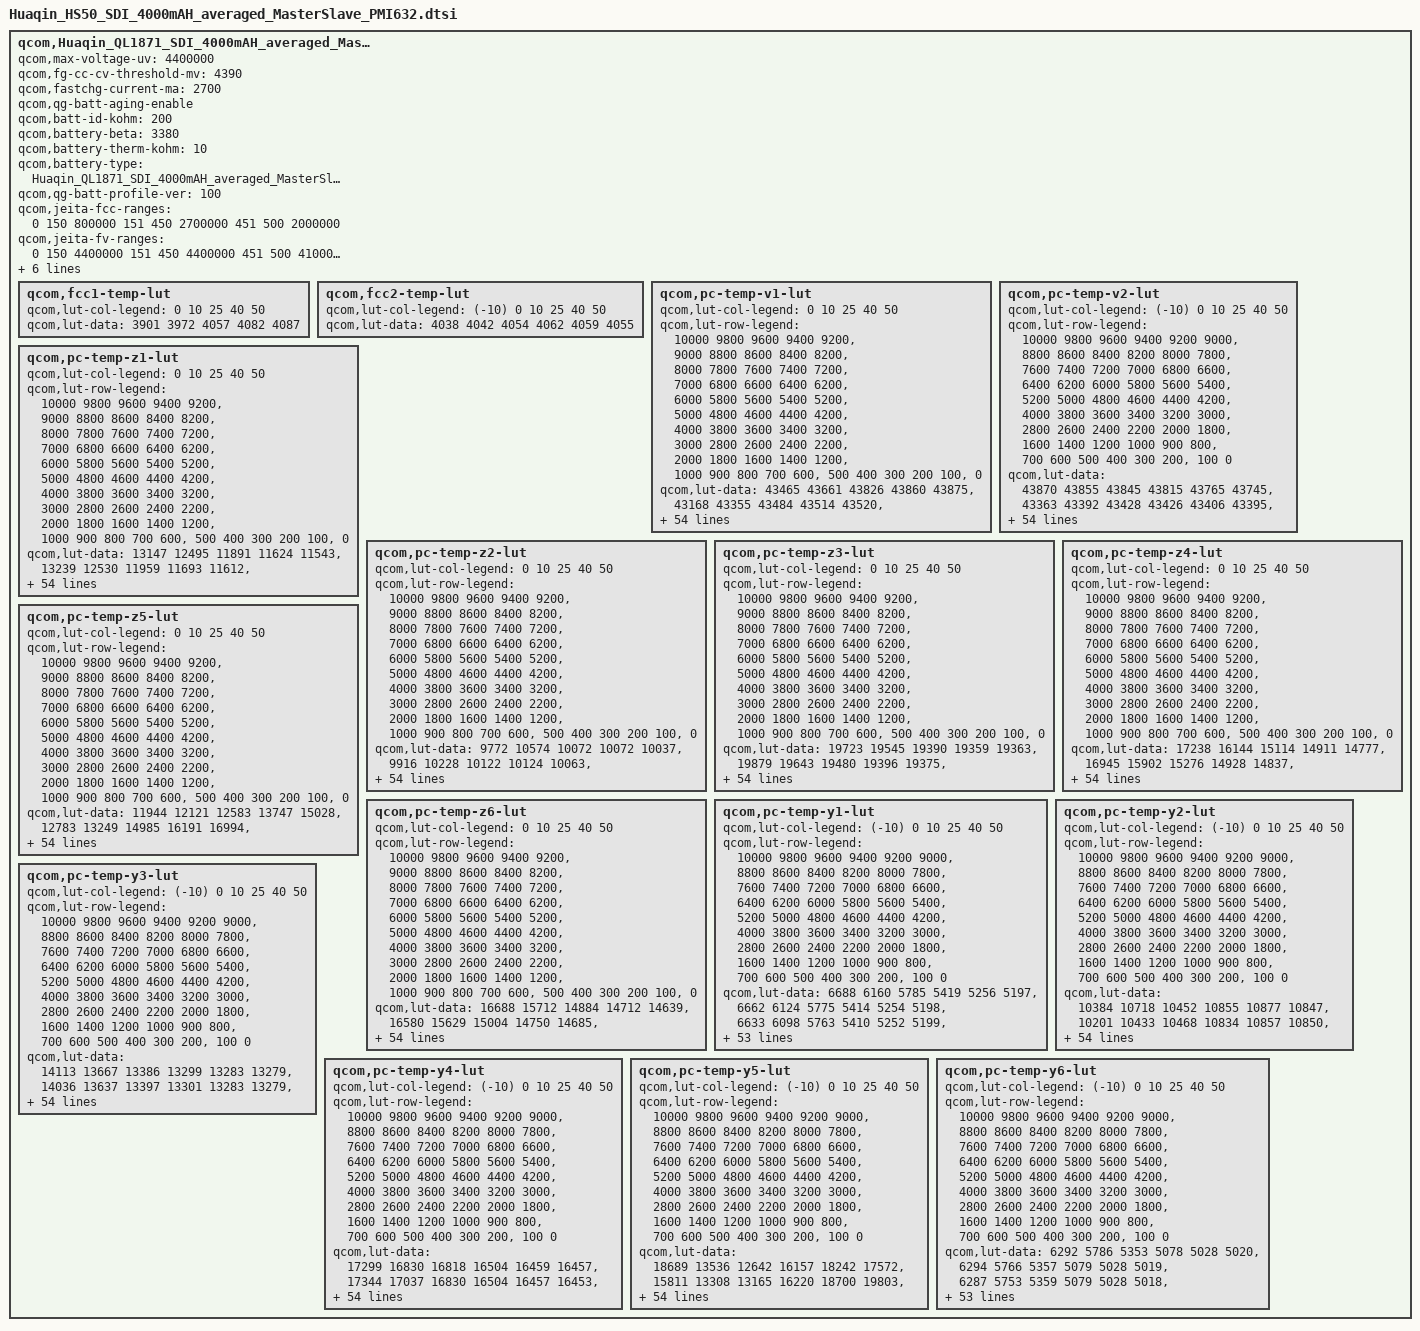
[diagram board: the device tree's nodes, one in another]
qcom,Huaqin_QL1871_SDI_4000mAH_averaged_MasterSlave_PMI632 {
        /* Huaqin_QL1871_SDI_4000mAH_averaged_MasterSlave_PMI632 */
	qcom,max-voltage-uv = <4400000>;
	qcom,fg-cc-cv-threshold-mv = <4390>;
	qcom,fastchg-current-ma = <2700>;
	/* HS60 add for SR-ZQL1695-01-357 Import battery aging by gaochao at 2019/08/29 start */
	qcom,qg-batt-aging-enable;
	/* HS60 add for SR-ZQL1695-01-357 Import battery aging by gaochao at 2019/08/29 end */
	qcom,batt-id-kohm = <200>;
	qcom,battery-beta = <3380>;
	qcom,battery-therm-kohm = <10>;
	qcom,battery-type = "Huaqin_QL1871_SDI_4000mAH_averaged_MasterSlave__PMI632";
	qcom,qg-batt-profile-ver = <100>;

	qcom,jeita-fcc-ranges = <0   150   800000
				 151 450  2700000
				 451 500  2000000>;
	qcom,jeita-fv-ranges =  <0   150  4400000
				 151 450  4400000
				 451 500  4100000>;

	/* HS60 add for SR-ZQL1695-01-357 Import battery aging by gaochao at 2019/08/29 start */
	qcom,vfloat-ranges = <0 299 4400000
	                      300 399 4380000
                              400 699 4360000
                              700 999 4340000
                              1000 9999 4290000>;

	qcom,vbat-rechg-ranges = <0 299 4330000
                                  300 399 4310000
                                  400 699 4290000
                                  700 999 4270000
                                  1000 9999 4220000>;
	/* HS60 add for SR-ZQL1695-01-357 Import battery aging by gaochao at 2019/08/29 end */

	/* COOL = 15 DegC, WARM = 45 DegC */
	qcom,jeita-soft-thresholds = <0x2554 0xFDC>;
	/* COLD = 0 DegC, HOT = 50 DegC */
	/* Huaqin add for HS70-733 modify jeita-hard-thresholds to 50 by qianyingdong at 2019/11/26 start */
	qcom,jeita-hard-thresholds = <0x36B9 0xDBF>;
	/* Huaqin add for HS70-733 modify jeita-hard-thresholds to 50 by qianyingdong at 2019/11/26 end */

	qcom,fcc1-temp-lut {
		qcom,lut-col-legend = <0 10 25 40 50>;
		qcom,lut-data = <3901 3972 4057 4082 4087>;
	};

	qcom,fcc2-temp-lut {
		qcom,lut-col-legend = <(-10) 0 10 25 40 50>;
		qcom,lut-data = <4038 4042 4054 4062 4059 4055>;
	};

	qcom,pc-temp-v1-lut {
		qcom,lut-col-legend = <0 10 25 40 50>;
		qcom,lut-row-legend = <10000 9800 9600 9400 9200>,
			<9000 8800 8600 8400 8200>,
			<8000 7800 7600 7400 7200>,
			<7000 6800 6600 6400 6200>,
			<6000 5800 5600 5400 5200>,
			<5000 4800 4600 4400 4200>,
			<4000 3800 3600 3400 3200>,
			<3000 2800 2600 2400 2200>,
			<2000 1800 1600 1400 1200>,
			<1000 900 800 700 600>,
			<500 400 300 200 100>,
			<0>;
		qcom,lut-data = <43465 43661 43826 43860 43875>,
			<43168 43355 43484 43514 43520>,
			<42910 43074 43198 43228 43235>,
			<42678 42820 42935 42965 42977>,
			<42456 42587 42684 42715 42730>,
			<42244 42362 42447 42478 42496>,
			<42039 42146 42218 42248 42267>,
			<41832 41935 41998 42019 42037>,
			<41621 41723 41782 41795 41810>,
			<41430 41511 41566 41573 41586>,
			<41292 41326 41355 41352 41366>,
			<41162 41190 41176 41150 41153>,
			<40946 41045 41037 40985 40953>,
			<40531 40780 40871 40815 40756>,
			<40153 40376 40555 40566 40541>,
			<39961 40085 40177 40253 40314>,
			<39822 39926 39975 40036 40118>,
			<39706 39804 39865 39914 39962>,
			<39613 39698 39761 39803 39818>,
			<39524 39610 39640 39668 39670>,
			<39416 39504 39510 39520 39523>,
			<39296 39360 39338 39344 39351>,
			<39171 39189 39109 39114 39129>,
			<39043 38984 38904 38900 38916>,
			<38910 38732 38744 38749 38760>,
			<38758 38565 38610 38624 38630>,
			<38584 38492 38511 38516 38517>,
			<38456 38440 38434 38420 38418>,
			<38383 38388 38362 38334 38329>,
			<38330 38341 38290 38256 38246>,
			<38291 38299 38225 38186 38172>,
			<38262 38261 38169 38124 38105>,
			<38239 38226 38120 38069 38047>,
			<38217 38194 38078 38019 37992>,
			<38200 38165 38043 37977 37945>,
			<38180 38137 38011 37936 37900>,
			<38163 38114 37978 37893 37850>,
			<38139 38089 37946 37847 37796>,
			<38097 38046 37900 37790 37732>,
			<38028 37971 37828 37715 37652>,
			<37945 37879 37739 37624 37558>,
			<37831 37772 37638 37521 37452>,
			<37696 37643 37515 37400 37328>,
			<37532 37485 37359 37246 37174>,
			<37379 37325 37205 37099 37030>,
			<37268 37211 37096 37000 36937>,
			<37240 37175 37070 36972 36911>,
			<37211 37152 37048 36954 36892>,
			<37190 37131 37030 36937 36874>,
			<37165 37105 37006 36904 36835>,
			<37030 36973 36840 36710 36618>,
			<36615 36574 36434 36298 36200>,
			<36068 36009 35881 35738 35639>,
			<35323 35237 35119 34974 34874>,
			<34124 34060 33946 33795 33696>,
			<30000 30000 30000 30000 30000>;
	};

	qcom,pc-temp-v2-lut {
		qcom,lut-col-legend = <(-10) 0 10 25 40 50>;
		qcom,lut-row-legend = <10000 9800 9600 9400 9200 9000>,
			<8800 8600 8400 8200 8000 7800>,
			<7600 7400 7200 7000 6800 6600>,
			<6400 6200 6000 5800 5600 5400>,
			<5200 5000 4800 4600 4400 4200>,
			<4000 3800 3600 3400 3200 3000>,
			<2800 2600 2400 2200 2000 1800>,
			<1600 1400 1200 1000 900 800>,
			<700 600 500 400 300 200>,
			<100 0>;
		qcom,lut-data = <43870 43855 43845 43815 43765 43745>,
			<43363 43392 43428 43426 43406 43395>,
			<42944 42992 43064 43084 43084 43079>,
			<42637 42667 42764 42799 42804 42802>,
			<42408 42395 42515 42559 42562 42559>,
			<42187 42166 42280 42329 42328 42324>,
			<41933 41984 42046 42099 42095 42090>,
			<41692 41816 41820 41873 41868 41861>,
			<41520 41591 41594 41648 41643 41636>,
			<41386 41303 41365 41425 41421 41415>,
			<41275 41144 41168 41214 41204 41198>,
			<41198 41113 41025 41028 40992 40986>,
			<41108 41086 40880 40839 40783 40777>,
			<40795 40858 40649 40609 40564 40570>,
			<40045 40176 40320 40342 40339 40361>,
			<39572 39740 40040 40105 40141 40169>,
			<39438 39618 39831 39899 39974 39997>,
			<39338 39522 39651 39724 39819 39833>,
			<39205 39366 39493 39601 39668 39674>,
			<39056 39163 39354 39502 39523 39522>,
			<38877 38981 39196 39365 39358 39356>,
			<38609 38839 39004 39146 39163 39172>,
			<38370 38697 38812 38921 38965 38983>,
			<38278 38495 38650 38742 38775 38791>,
			<38226 38256 38502 38584 38594 38600>,
			<38178 38131 38377 38454 38454 38455>,
			<38130 38083 38274 38346 38347 38346>,
			<38085 38048 38176 38252 38254 38252>,
			<38040 38011 38067 38166 38167 38164>,
			<37997 37975 37961 38089 38088 38084>,
			<37952 37940 37903 38017 38018 38012>,
			<37904 37906 37871 37949 37954 37948>,
			<37855 37870 37844 37888 37895 37888>,
			<37806 37832 37816 37834 37839 37831>,
			<37756 37791 37790 37786 37783 37776>,
			<37705 37747 37756 37740 37717 37701>,
			<37650 37699 37715 37697 37641 37599>,
			<37593 37646 37666 37647 37561 37499>,
			<37529 37585 37600 37580 37483 37414>,
			<37460 37518 37519 37503 37404 37335>,
			<37391 37447 37430 37422 37325 37257>,
			<37322 37367 37329 37334 37244 37180>,
			<37253 37279 37230 37220 37139 37076>,
			<37186 37180 37130 37084 37008 36943>,
			<37115 37069 37028 36955 36872 36810>,
			<37035 36962 36937 36886 36818 36761>,
			<36991 36915 36893 36870 36805 36752>,
			<36942 36870 36848 36855 36792 36738>,
			<36881 36826 36799 36830 36768 36713>,
			<36791 36755 36715 36776 36707 36642>,
			<36612 36614 36548 36579 36472 36380>,
			<36271 36285 36202 36123 35994 35891>,
			<35732 35731 35632 35499 35362 35253>,
			<34929 34932 34821 34644 34495 34379>,
			<33597 33640 33535 33359 33206 33068>,
			<29083 28754 28799 29150 29064 29071>;
	};

	qcom,pc-temp-z1-lut {
		qcom,lut-col-legend = <0 10 25 40 50>;
		qcom,lut-row-legend = <10000 9800 9600 9400 9200>,
			<9000 8800 8600 8400 8200>,
			<8000 7800 7600 7400 7200>,
			<7000 6800 6600 6400 6200>,
			<6000 5800 5600 5400 5200>,
			<5000 4800 4600 4400 4200>,
			<4000 3800 3600 3400 3200>,
			<3000 2800 2600 2400 2200>,
			<2000 1800 1600 1400 1200>,
			<1000 900 800 700 600>,
			<500 400 300 200 100>,
			<0>;
		qcom,lut-data = <13147 12495 11891 11624 11543>,
			<13239 12530 11959 11693 11612>,
			<13247 12548 11956 11696 11616>,
			<13224 12543 11950 11698 11617>,
			<13212 12537 11946 11696 11617>,
			<13202 12535 11940 11692 11617>,
			<13189 12531 11934 11690 11617>,
			<13185 12525 11928 11688 11616>,
			<13179 12525 11924 11688 11616>,
			<13177 12526 11923 11687 11615>,
			<13169 12523 11924 11687 11614>,
			<13152 12513 11922 11686 11613>,
			<13135 12497 11917 11685 11614>,
			<13099 12475 11911 11683 11615>,
			<13063 12446 11899 11678 11614>,
			<13036 12433 11887 11669 11610>,
			<13014 12435 11885 11666 11608>,
			<13009 12439 11892 11669 11610>,
			<13030 12446 11898 11673 11612>,
			<13055 12463 11902 11675 11613>,
			<13067 12473 11906 11678 11614>,
			<13071 12472 11909 11679 11614>,
			<13070 12469 11911 11679 11615>,
			<13070 12472 11914 11680 11615>,
			<13071 12477 11917 11682 11617>,
			<13074 12481 11922 11686 11620>,
			<13079 12478 11926 11689 11623>,
			<13087 12473 11931 11692 11626>,
			<13101 12478 11935 11696 11629>,
			<13117 12494 11936 11699 11631>,
			<13122 12507 11938 11703 11633>,
			<13116 12514 11941 11707 11636>,
			<13111 12520 11946 11710 11641>,
			<13115 12519 11952 11714 11644>,
			<13124 12511 11957 11716 11647>,
			<13131 12507 11962 11719 11649>,
			<13141 12511 11969 11723 11651>,
			<13152 12519 11978 11727 11653>,
			<13162 12531 11981 11730 11656>,
			<13172 12553 11980 11733 11659>,
			<13187 12568 11979 11735 11661>,
			<13226 12573 11986 11739 11664>,
			<13244 12576 11996 11742 11667>,
			<13232 12570 11998 11745 11669>,
			<13237 12580 12002 11749 11671>,
			<13216 12613 12010 11750 11672>,
			<13261 12583 12011 11750 11672>,
			<13251 12609 12018 11752 11672>,
			<13249 12595 12014 11753 11673>,
			<13258 12587 12026 11758 11677>,
			<13266 12601 12028 11765 11683>,
			<13264 12645 12030 11774 11690>,
			<13307 12625 12050 11783 11702>,
			<13306 12702 12072 11802 11717>,
			<13306 12702 12072 11802 11717>,
			<13306 12702 12072 11802 11717>;
	};

	qcom,pc-temp-z2-lut {
		qcom,lut-col-legend = <0 10 25 40 50>;
		qcom,lut-row-legend = <10000 9800 9600 9400 9200>,
			<9000 8800 8600 8400 8200>,
			<8000 7800 7600 7400 7200>,
			<7000 6800 6600 6400 6200>,
			<6000 5800 5600 5400 5200>,
			<5000 4800 4600 4400 4200>,
			<4000 3800 3600 3400 3200>,
			<3000 2800 2600 2400 2200>,
			<2000 1800 1600 1400 1200>,
			<1000 900 800 700 600>,
			<500 400 300 200 100>,
			<0>;
		qcom,lut-data = <9772 10574 10072 10072 10037>,
			<9916 10228 10122 10124 10063>,
			<9965 10026 10152 10175 10066>,
			<9989 10012 10166 10237 10061>,
			<10005 10010 10156 10244 10053>,
			<10019 10006 10133 10205 10035>,
			<10030 9994 10149 10170 10023>,
			<10030 9983 10331 10156 10023>,
			<10026 9982 10484 10144 10026>,
			<10019 9984 10618 10126 10028>,
			<10006 9987 10871 10105 10034>,
			<9987 9991 10944 10099 10042>,
			<9966 9998 10907 10078 10049>,
			<9939 10014 10839 10052 10058>,
			<9920 10043 10595 10083 10077>,
			<9915 10056 10249 10168 10114>,
			<9913 10054 10163 10197 10130>,
			<9914 10051 10153 10143 10120>,
			<9921 10062 10152 10091 10110>,
			<9934 10109 10175 10099 10118>,
			<9951 10155 10217 10130 10147>,
			<9977 10195 10269 10173 10179>,
			<10004 10229 10354 10263 10216>,
			<10033 10247 10397 10322 10248>,
			<10061 10259 10329 10297 10270>,
			<10086 10264 10241 10248 10290>,
			<10110 10256 10242 10228 10284>,
			<10128 10245 10289 10265 10205>,
			<10140 10244 10319 10299 10127>,
			<10149 10245 10327 10253 10086>,
			<10156 10248 10331 10176 10056>,
			<10161 10252 10330 10147 10053>,
			<10167 10259 10323 10126 10061>,
			<10175 10269 10321 10118 10074>,
			<10184 10286 10333 10136 10096>,
			<10194 10298 10349 10169 10128>,
			<10206 10305 10364 10210 10172>,
			<10219 10310 10380 10267 10236>,
			<10234 10320 10394 10297 10274>,
			<10251 10338 10417 10309 10290>,
			<10264 10348 10433 10316 10298>,
			<10273 10348 10427 10317 10295>,
			<10285 10347 10418 10317 10287>,
			<10310 10355 10420 10309 10284>,
			<10497 10435 10441 10313 10283>,
			<10557 10507 10470 10326 10262>,
			<10557 10505 10453 10326 10264>,
			<10556 10502 10437 10337 10268>,
			<10561 10511 10429 10336 10265>,
			<10607 10516 10427 10383 10363>,
			<10620 10544 10453 10356 10268>,
			<10567 10489 10380 10227 10113>,
			<10365 10433 10339 10154 10059>,
			<9693 10367 10264 10112 10019>,
			<9693 10367 10264 10112 10019>,
			<9693 10367 10264 10112 10019>;
	};

	qcom,pc-temp-z3-lut {
		qcom,lut-col-legend = <0 10 25 40 50>;
		qcom,lut-row-legend = <10000 9800 9600 9400 9200>,
			<9000 8800 8600 8400 8200>,
			<8000 7800 7600 7400 7200>,
			<7000 6800 6600 6400 6200>,
			<6000 5800 5600 5400 5200>,
			<5000 4800 4600 4400 4200>,
			<4000 3800 3600 3400 3200>,
			<3000 2800 2600 2400 2200>,
			<2000 1800 1600 1400 1200>,
			<1000 900 800 700 600>,
			<500 400 300 200 100>,
			<0>;
		qcom,lut-data = <19723 19545 19390 19359 19363>,
			<19879 19643 19480 19396 19375>,
			<19893 19700 19493 19411 19386>,
			<19880 19702 19498 19420 19391>,
			<19865 19697 19498 19421 19392>,
			<19841 19691 19496 19421 19393>,
			<19813 19680 19497 19420 19393>,
			<19795 19667 19505 19416 19392>,
			<19784 19658 19510 19411 19388>,
			<19771 19651 19512 19407 19385>,
			<19745 19641 19515 19404 19379>,
			<19717 19613 19513 19400 19376>,
			<19716 19588 19505 19388 19374>,
			<19755 19589 19493 19377 19373>,
			<19786 19598 19481 19380 19373>,
			<19775 19601 19467 19393 19375>,
			<19743 19588 19451 19396 19375>,
			<19712 19567 19430 19380 19367>,
			<19674 19548 19417 19364 19357>,
			<19647 19528 19412 19362 19352>,
			<19645 19520 19409 19361 19348>,
			<19646 19527 19414 19362 19348>,
			<19648 19537 19433 19371 19353>,
			<19653 19546 19444 19378 19357>,
			<19660 19554 19431 19368 19356>,
			<19668 19558 19413 19352 19353>,
			<19678 19554 19411 19352 19354>,
			<19683 19548 19413 19377 19373>,
			<19680 19545 19416 19395 19387>,
			<19672 19542 19430 19397 19386>,
			<19665 19541 19443 19396 19384>,
			<19656 19540 19445 19394 19381>,
			<19648 19540 19445 19389 19375>,
			<19641 19540 19445 19384 19369>,
			<19635 19539 19442 19379 19363>,
			<19630 19539 19437 19374 19356>,
			<19624 19536 19432 19371 19352>,
			<19618 19531 19428 19368 19348>,
			<19614 19527 19424 19366 19347>,
			<19610 19524 19422 19365 19348>,
			<19604 19521 19419 19364 19349>,
			<19595 19516 19414 19363 19350>,
			<19585 19511 19410 19362 19354>,
			<19577 19504 19408 19363 19357>,
			<19527 19482 19401 19361 19357>,
			<19506 19459 19393 19353 19347>,
			<19494 19459 19387 19347 19338>,
			<19494 19456 19386 19343 19333>,
			<19488 19451 19385 19341 19330>,
			<19466 19446 19367 19336 19323>,
			<19472 19445 19375 19345 19342>,
			<19488 19449 19386 19359 19352>,
			<19426 19452 19371 19360 19354>,
			<19278 19446 19375 19362 19355>,
			<19278 19446 19375 19362 19355>,
			<19278 19446 19375 19362 19355>;
	};

	qcom,pc-temp-z4-lut {
		qcom,lut-col-legend = <0 10 25 40 50>;
		qcom,lut-row-legend = <10000 9800 9600 9400 9200>,
			<9000 8800 8600 8400 8200>,
			<8000 7800 7600 7400 7200>,
			<7000 6800 6600 6400 6200>,
			<6000 5800 5600 5400 5200>,
			<5000 4800 4600 4400 4200>,
			<4000 3800 3600 3400 3200>,
			<3000 2800 2600 2400 2200>,
			<2000 1800 1600 1400 1200>,
			<1000 900 800 700 600>,
			<500 400 300 200 100>,
			<0>;
		qcom,lut-data = <17238 16144 15114 14911 14777>,
			<16945 15902 15276 14928 14837>,
			<16599 15682 15153 14909 14843>,
			<16206 15479 15005 14854 14818>,
			<15898 15292 14934 14817 14795>,
			<15688 15156 14881 14790 14774>,
			<15523 15060 14831 14767 14756>,
			<15398 14987 14778 14747 14740>,
			<15300 14934 14738 14732 14726>,
			<15216 14893 14711 14725 14719>,
			<15137 14856 14685 14721 14715>,
			<15069 14813 14664 14717 14711>,
			<15013 14784 14644 14709 14702>,
			<14968 14786 14634 14703 14694>,
			<14928 14799 14670 14708 14694>,
			<14886 14804 14732 14723 14698>,
			<14847 14786 14740 14727 14699>,
			<14827 14760 14714 14701 14685>,
			<14820 14743 14694 14673 14668>,
			<14813 14728 14688 14665 14661>,
			<14799 14723 14685 14661 14657>,
			<14779 14728 14692 14665 14660>,
			<14771 14738 14731 14714 14711>,
			<14771 14773 14771 14766 14761>,
			<14771 14861 14810 14791 14771>,
			<14785 14906 14841 14809 14775>,
			<14836 14894 14839 14805 14772>,
			<14865 14873 14820 14765 14738>,
			<14864 14856 14798 14729 14706>,
			<14862 14841 14773 14714 14694>,
			<14858 14826 14751 14704 14686>,
			<14846 14812 14739 14697 14681>,
			<14832 14800 14731 14692 14676>,
			<14820 14790 14727 14689 14674>,
			<14808 14782 14725 14688 14674>,
			<14796 14775 14724 14687 14674>,
			<14783 14770 14724 14688 14675>,
			<14774 14766 14726 14693 14681>,
			<14768 14767 14729 14698 14687>,
			<14763 14770 14735 14706 14694>,
			<14762 14772 14739 14712 14700>,
			<14763 14766 14734 14708 14695>,
			<14763 14756 14723 14699 14686>,
			<14754 14747 14717 14698 14687>,
			<14726 14725 14701 14692 14683>,
			<14716 14707 14684 14675 14667>,
			<14717 14700 14680 14673 14668>,
			<14707 14693 14668 14664 14659>,
			<14705 14686 14657 14647 14642>,
			<14718 14683 14664 14642 14636>,
			<14712 14690 14672 14657 14648>,
			<14723 14703 14675 14655 14650>,
			<14803 14705 14693 14656 14650>,
			<14974 14710 14690 14655 14649>,
			<14974 14710 14690 14655 14649>,
			<14974 14710 14690 14655 14649>;
	};

	qcom,pc-temp-z5-lut {
		qcom,lut-col-legend = <0 10 25 40 50>;
		qcom,lut-row-legend = <10000 9800 9600 9400 9200>,
			<9000 8800 8600 8400 8200>,
			<8000 7800 7600 7400 7200>,
			<7000 6800 6600 6400 6200>,
			<6000 5800 5600 5400 5200>,
			<5000 4800 4600 4400 4200>,
			<4000 3800 3600 3400 3200>,
			<3000 2800 2600 2400 2200>,
			<2000 1800 1600 1400 1200>,
			<1000 900 800 700 600>,
			<500 400 300 200 100>,
			<0>;
		qcom,lut-data = <11944 12121 12583 13747 15028>,
			<12783 13249 14985 16191 16994>,
			<13216 14218 15867 17368 18248>,
			<13482 14993 16527 18555 19010>,
			<13727 15645 17163 19298 19578>,
			<13972 16303 17754 19763 19972>,
			<14218 16949 18755 20211 20393>,
			<14545 17645 20978 20796 21185>,
			<14994 18680 23411 21321 21981>,
			<15259 19994 25851 21600 22041>,
			<15269 20478 29201 21790 21710>,
			<15259 20284 32965 21715 21529>,
			<15663 20068 38027 20509 22080>,
			<18435 20975 40905 19142 23206>,
			<20692 23891 35767 20276 24784>,
			<20718 25216 26543 23824 27133>,
			<20596 24376 23290 25029 28082>,
			<20348 23353 22076 23286 27294>,
			<19310 23193 21639 21683 26395>,
			<18357 23299 22468 22501 26896>,
			<18921 23666 24278 25032 28533>,
			<21243 29042 28460 27786 29356>,
			<24130 36269 39872 31444 29446>,
			<27943 39106 45940 33607 29176>,
			<32587 40750 36496 28043 25457>,
			<37967 41284 23622 18233 18490>,
			<44667 37279 20552 16442 16941>,
			<47829 31543 19459 18338 19139>,
			<45536 29383 19196 20230 21690>,
			<41383 28239 21108 21676 23540>,
			<38334 27830 24134 23180 25197>,
			<35771 28247 26638 24369 26501>,
			<33917 29130 29118 25803 27637>,
			<32772 30367 31073 27046 28262>,
			<31953 32413 32803 28241 28512>,
			<31795 33813 33849 29163 28659>,
			<32036 34354 33701 29214 28443>,
			<32435 34694 33019 28750 27422>,
			<33246 34666 32058 28062 26220>,
			<34503 34172 30235 26408 24509>,
			<34804 33466 28262 24579 23163>,
			<32303 32312 26521 23397 23338>,
			<30849 30950 25280 22638 24004>,
			<31613 29574 25269 22759 24905>,
			<31721 30086 25627 22775 25327>,
			<30564 28865 26333 21950 23000>,
			<26609 29328 24309 20405 19449>,
			<27407 28405 25409 20245 19361>,
			<26290 27931 27129 22713 22227>,
			<21323 27201 21263 22780 22393>,
			<23045 25725 21284 20826 23237>,
			<23669 22618 20563 21107 22294>,
			<17188 21394 16792 20223 21227>,
			<11348 19636 16847 19686 20016>,
			<11348 19636 16847 19686 20016>,
			<11348 19636 16847 19686 20016>;
	};

	qcom,pc-temp-z6-lut {
		qcom,lut-col-legend = <0 10 25 40 50>;
		qcom,lut-row-legend = <10000 9800 9600 9400 9200>,
			<9000 8800 8600 8400 8200>,
			<8000 7800 7600 7400 7200>,
			<7000 6800 6600 6400 6200>,
			<6000 5800 5600 5400 5200>,
			<5000 4800 4600 4400 4200>,
			<4000 3800 3600 3400 3200>,
			<3000 2800 2600 2400 2200>,
			<2000 1800 1600 1400 1200>,
			<1000 900 800 700 600>,
			<500 400 300 200 100>,
			<0>;
		qcom,lut-data = <16688 15712 14884 14712 14639>,
			<16580 15629 15004 14750 14685>,
			<16416 15541 14955 14746 14692>,
			<16193 15444 14894 14730 14685>,
			<16006 15342 14860 14716 14679>,
			<15871 15261 14833 14704 14670>,
			<15760 15201 14811 14693 14662>,
			<15675 15153 14791 14682 14654>,
			<15607 15116 14775 14672 14647>,
			<15546 15086 14764 14667 14641>,
			<15482 15055 14756 14663 14636>,
			<15423 15013 14744 14659 14632>,
			<15382 14982 14727 14648 14627>,
			<15353 14978 14717 14639 14623>,
			<15326 14978 14724 14643 14623>,
			<15291 14976 14735 14654 14624>,
			<15255 14961 14734 14657 14624>,
			<15230 14938 14711 14637 14614>,
			<15212 14922 14694 14616 14601>,
			<15200 14908 14690 14612 14595>,
			<15195 14903 14688 14609 14591>,
			<15193 14908 14693 14612 14592>,
			<15192 14920 14722 14640 14616>,
			<15195 14942 14745 14664 14640>,
			<15202 14985 14754 14668 14644>,
			<15217 15006 14760 14670 14646>,
			<15247 15000 14759 14669 14646>,
			<15263 14991 14753 14665 14642>,
			<15262 14984 14747 14661 14637>,
			<15260 14977 14744 14657 14633>,
			<15256 14971 14742 14652 14628>,
			<15248 14966 14740 14648 14624>,
			<15240 14962 14738 14644 14619>,
			<15234 14960 14736 14640 14615>,
			<15228 14958 14733 14636 14611>,
			<15224 14957 14731 14634 14608>,
			<15219 14954 14730 14634 14607>,
			<15216 14953 14729 14634 14608>,
			<15216 14953 14729 14635 14608>,
			<15218 14956 14731 14637 14611>,
			<15219 14958 14732 14640 14614>,
			<15219 14956 14729 14638 14614>,
			<15220 14952 14723 14635 14612>,
			<15220 14949 14721 14635 14614>,
			<15202 14939 14713 14632 14613>,
			<15191 14926 14704 14621 14601>,
			<15186 14924 14699 14617 14597>,
			<15182 14920 14694 14611 14590>,
			<15178 14915 14689 14603 14581>,
			<15176 14915 14684 14598 14575>,
			<15185 14922 14694 14611 14591>,
			<15206 14937 14704 14620 14601>,
			<15221 14948 14708 14624 14604>,
			<15245 14964 14716 14628 14608>,
			<15245 14964 14716 14628 14608>,
			<15245 14964 14716 14628 14608>;
	};

	qcom,pc-temp-y1-lut {
		qcom,lut-col-legend = <(-10) 0 10 25 40 50>;
		qcom,lut-row-legend = <10000 9800 9600 9400 9200 9000>,
			<8800 8600 8400 8200 8000 7800>,
			<7600 7400 7200 7000 6800 6600>,
			<6400 6200 6000 5800 5600 5400>,
			<5200 5000 4800 4600 4400 4200>,
			<4000 3800 3600 3400 3200 3000>,
			<2800 2600 2400 2200 2000 1800>,
			<1600 1400 1200 1000 900 800>,
			<700 600 500 400 300 200>,
			<100 0>;
		qcom,lut-data = <6688 6160 5785 5419 5256 5197>,
			<6662 6124 5775 5414 5254 5198>,
			<6633 6098 5763 5410 5252 5199>,
			<6606 6081 5752 5406 5250 5198>,
			<6587 6070 5743 5402 5249 5198>,
			<6580 6067 5740 5400 5247 5197>,
			<6600 6075 5741 5397 5246 5197>,
			<6628 6087 5743 5395 5244 5195>,
			<6629 6090 5741 5394 5243 5195>,
			<6610 6094 5736 5394 5241 5194>,
			<6600 6096 5731 5394 5240 5194>,
			<6617 6092 5726 5392 5238 5193>,
			<6638 6089 5723 5390 5237 5192>,
			<6635 6091 5727 5390 5235 5191>,
			<6617 6095 5739 5391 5234 5189>,
			<6610 6100 5745 5391 5234 5189>,
			<6626 6106 5748 5391 5235 5190>,
			<6647 6111 5750 5391 5237 5192>,
			<6651 6120 5750 5391 5236 5192>,
			<6653 6138 5749 5391 5234 5191>,
			<6655 6145 5750 5390 5233 5191>,
			<6663 6131 5754 5391 5234 5191>,
			<6669 6116 5757 5392 5235 5191>,
			<6667 6114 5756 5394 5237 5192>,
			<6664 6113 5754 5397 5238 5193>,
			<6657 6113 5756 5400 5240 5195>,
			<6622 6114 5764 5402 5242 5197>,
			<6590 6116 5773 5405 5244 5198>,
			<6597 6122 5782 5409 5246 5200>,
			<6621 6131 5791 5415 5248 5201>,
			<6636 6133 5792 5421 5251 5203>,
			<6652 6132 5784 5428 5255 5206>,
			<6663 6132 5779 5433 5258 5209>,
			<6654 6137 5784 5437 5262 5212>,
			<6629 6147 5793 5440 5265 5214>,
			<6618 6148 5796 5441 5269 5216>,
			<6610 6137 5795 5442 5272 5218>,
			<6601 6129 5794 5444 5274 5221>,
			<6596 6125 5792 5447 5277 5223>,
			<6596 6115 5788 5451 5279 5225>,
			<6602 6117 5786 5458 5282 5227>,
			<6613 6129 5786 5466 5284 5228>,
			<6616 6126 5794 5473 5287 5231>,
			<6606 6115 5806 5477 5291 5234>,
			<6615 6121 5810 5485 5298 5238>,
			<6611 6168 5802 5488 5302 5242>,
			<6624 6140 5804 5498 5304 5243>,
			<6626 6155 5806 5492 5304 5242>,
			<6632 6143 5814 5498 5303 5240>,
			<6655 6140 5819 5500 5303 5240>,
			<6667 6149 5818 5495 5303 5242>,
			<6629 6154 5838 5501 5314 5249>,
			<6648 6193 5850 5523 5326 5258>,
			<6714 6204 5851 5546 5336 5269>,
			<6714 6204 5851 5546 5336 5269>,
			<6714 6204 5851 5546 5336 5269>;
	};

	qcom,pc-temp-y2-lut {
		qcom,lut-col-legend = <(-10) 0 10 25 40 50>;
		qcom,lut-row-legend = <10000 9800 9600 9400 9200 9000>,
			<8800 8600 8400 8200 8000 7800>,
			<7600 7400 7200 7000 6800 6600>,
			<6400 6200 6000 5800 5600 5400>,
			<5200 5000 4800 4600 4400 4200>,
			<4000 3800 3600 3400 3200 3000>,
			<2800 2600 2400 2200 2000 1800>,
			<1600 1400 1200 1000 900 800>,
			<700 600 500 400 300 200>,
			<100 0>;
		qcom,lut-data = <10384 10718 10452 10855 10877 10847>,
			<10201 10433 10468 10834 10857 10850>,
			<10122 10243 10478 10812 10831 10845>,
			<10123 10130 10483 10792 10802 10835>,
			<10176 10075 10485 10773 10773 10820>,
			<10257 10063 10486 10756 10748 10802>,
			<10457 10157 10489 10742 10718 10767>,
			<10673 10286 10490 10728 10693 10732>,
			<10654 10298 10462 10716 10689 10725>,
			<10447 10264 10385 10704 10691 10726>,
			<10336 10247 10355 10691 10692 10724>,
			<10461 10286 10630 10668 10677 10702>,
			<10620 10368 10950 10647 10661 10677>,
			<10494 10482 10921 10670 10662 10682>,
			<9963 10673 10742 10753 10675 10705>,
			<9697 10940 10670 10815 10695 10718>,
			<9689 11539 10726 10851 10758 10714>,
			<9684 12091 10811 10889 10838 10711>,
			<9681 11848 10888 10955 10899 10736>,
			<9679 10882 10971 11043 10955 10805>,
			<9677 10330 11031 11077 11012 10874>,
			<9674 10198 11070 11084 11085 10953>,
			<9672 10103 11104 11087 11130 11008>,
			<9670 9959 11157 11086 11086 10996>,
			<9669 9785 11220 11086 10993 10955>,
			<9668 9716 11220 11093 10970 10948>,
			<9667 9701 11056 11121 10993 10961>,
			<9666 9692 10920 11161 11026 10977>,
			<9665 9686 10928 11220 11062 11000>,
			<9664 9682 10951 11290 11107 11042>,
			<9664 9678 10912 11323 11151 11091>,
			<9663 9674 10643 11342 11199 11168>,
			<9663 9671 10460 11349 11251 11233>,
			<9663 9669 10581 11336 11322 11274>,
			<9662 9667 10766 11310 11387 11304>,
			<9662 9666 10715 11279 11379 11297>,
			<9662 9665 10408 11228 11287 11227>,
			<9661 9664 10219 11171 11210 11162>,
			<9661 9663 10100 11112 11177 11134>,
			<9661 9662 9914 11052 11154 11111>,
			<9661 9661 9829 11006 11130 11073>,
			<9661 9661 9744 10964 11103 11024>,
			<9661 9661 9714 10893 11100 11027>,
			<9661 9660 9699 10804 11104 11039>,
			<9660 9660 9693 10772 11019 10989>,
			<9660 9661 9695 10755 10906 10841>,
			<9660 9660 9691 10691 10875 10806>,
			<9660 9660 9687 10688 10864 10792>,
			<9659 9660 9688 10704 10923 10803>,
			<9659 9659 9688 10722 10956 10785>,
			<9658 9659 9686 10688 10933 10771>,
			<9658 9659 9683 10586 10855 10732>,
			<9657 9658 9673 10487 10751 10650>,
			<9656 9657 9666 10429 10707 10543>,
			<9656 9657 9666 10429 10707 10543>,
			<9656 9657 9666 10429 10707 10543>;
	};

	qcom,pc-temp-y3-lut {
		qcom,lut-col-legend = <(-10) 0 10 25 40 50>;
		qcom,lut-row-legend = <10000 9800 9600 9400 9200 9000>,
			<8800 8600 8400 8200 8000 7800>,
			<7600 7400 7200 7000 6800 6600>,
			<6400 6200 6000 5800 5600 5400>,
			<5200 5000 4800 4600 4400 4200>,
			<4000 3800 3600 3400 3200 3000>,
			<2800 2600 2400 2200 2000 1800>,
			<1600 1400 1200 1000 900 800>,
			<700 600 500 400 300 200>,
			<100 0>;
		qcom,lut-data = <14113 13667 13386 13299 13283 13279>,
			<14036 13637 13397 13301 13283 13279>,
			<13971 13619 13404 13302 13284 13279>,
			<13921 13609 13409 13303 13284 13280>,
			<13888 13606 13412 13304 13285 13280>,
			<13878 13606 13413 13304 13286 13280>,
			<13897 13647 13410 13305 13287 13280>,
			<13924 13704 13407 13306 13288 13280>,
			<13864 13668 13416 13307 13288 13281>,
			<13599 13484 13448 13307 13289 13282>,
			<13456 13386 13463 13309 13290 13283>,
			<13477 13428 13427 13314 13291 13284>,
			<13504 13481 13382 13319 13291 13286>,
			<13493 13483 13380 13319 13292 13287>,
			<13442 13466 13395 13316 13292 13288>,
			<13418 13452 13401 13314 13293 13288>,
			<13431 13441 13392 13311 13294 13288>,
			<13452 13427 13381 13309 13296 13288>,
			<13469 13399 13375 13309 13296 13289>,
			<13485 13353 13371 13311 13295 13290>,
			<13489 13335 13366 13311 13294 13290>,
			<13474 13342 13359 13308 13292 13288>,
			<13456 13349 13349 13304 13289 13286>,
			<13463 13348 13337 13301 13286 13283>,
			<13489 13341 13323 13298 13283 13280>,
			<13514 13338 13317 13296 13281 13279>,
			<13536 13337 13315 13295 13281 13279>,
			<13559 13338 13314 13294 13281 13280>,
			<13586 13352 13313 13294 13281 13279>,
			<13617 13382 13312 13294 13280 13279>,
			<13648 13410 13311 13293 13280 13279>,
			<13679 13434 13312 13292 13280 13279>,
			<13710 13459 13313 13291 13280 13279>,
			<13740 13487 13319 13291 13281 13279>,
			<13768 13517 13328 13291 13281 13279>,
			<13797 13547 13332 13292 13281 13279>,
			<13825 13580 13334 13294 13281 13278>,
			<13853 13613 13336 13295 13281 13277>,
			<13878 13647 13342 13295 13281 13277>,
			<13902 13681 13350 13296 13280 13278>,
			<13927 13715 13360 13297 13281 13279>,
			<13953 13749 13375 13301 13283 13282>,
			<13980 13781 13392 13301 13284 13282>,
			<14011 13811 13413 13301 13285 13281>,
			<14055 13832 13431 13300 13282 13277>,
			<14029 13793 13432 13302 13284 13281>,
			<14082 13830 13445 13305 13286 13285>,
			<14133 13859 13463 13311 13290 13287>,
			<14193 13890 13482 13318 13293 13289>,
			<14251 13932 13498 13324 13295 13289>,
			<14314 13964 13511 13322 13293 13286>,
			<14387 13997 13517 13320 13292 13285>,
			<14499 14088 13559 13328 13295 13289>,
			<14697 14239 13666 13343 13302 13295>,
			<14697 14239 13666 13343 13302 13295>,
			<14697 14239 13666 13343 13302 13295>;
	};

	qcom,pc-temp-y4-lut {
		qcom,lut-col-legend = <(-10) 0 10 25 40 50>;
		qcom,lut-row-legend = <10000 9800 9600 9400 9200 9000>,
			<8800 8600 8400 8200 8000 7800>,
			<7600 7400 7200 7000 6800 6600>,
			<6400 6200 6000 5800 5600 5400>,
			<5200 5000 4800 4600 4400 4200>,
			<4000 3800 3600 3400 3200 3000>,
			<2800 2600 2400 2200 2000 1800>,
			<1600 1400 1200 1000 900 800>,
			<700 600 500 400 300 200>,
			<100 0>;
		qcom,lut-data = <17299 16830 16818 16504 16459 16457>,
			<17344 17037 16830 16504 16457 16453>,
			<17371 17165 16840 16504 16455 16450>,
			<17385 17235 16848 16504 16453 16448>,
			<17390 17263 16853 16504 16452 16447>,
			<17390 17268 16855 16504 16452 16446>,
			<17230 17193 16855 16505 16452 16447>,
			<17007 17091 16853 16506 16453 16448>,
			<17121 17161 16833 16508 16454 16449>,
			<17732 17514 16768 16513 16457 16451>,
			<18063 17726 16740 16517 16461 16452>,
			<18036 17759 16899 16520 16465 16453>,
			<17973 17776 17089 16522 16470 16455>,
			<17801 17646 17061 16526 16473 16457>,
			<17399 17187 16905 16534 16476 16461>,
			<17183 16971 16825 16544 16481 16466>,
			<17155 16999 16823 16564 16495 16473>,
			<17134 17031 16829 16590 16512 16482>,
			<17088 17032 16830 16618 16531 16496>,
			<17013 17025 16829 16648 16550 16513>,
			<16924 17013 16821 16652 16555 16521>,
			<16789 16955 16765 16603 16546 16524>,
			<16684 16868 16703 16546 16532 16525>,
			<16677 16763 16678 16515 16504 16506>,
			<16679 16640 16661 16491 16465 16463>,
			<16680 16603 16642 16486 16455 16449>,
			<16683 16622 16618 16487 16456 16449>,
			<16686 16639 16590 16488 16458 16450>,
			<16688 16638 16551 16492 16463 16453>,
			<16692 16633 16508 16497 16471 16460>,
			<16697 16632 16503 16501 16479 16468>,
			<16705 16641 16527 16503 16489 16477>,
			<16714 16652 16547 16504 16496 16486>,
			<16721 16662 16553 16503 16499 16495>,
			<16726 16672 16559 16501 16502 16502>,
			<16728 16681 16572 16501 16499 16500>,
			<16728 16688 16605 16504 16485 16478>,
			<16728 16695 16626 16506 16473 16463>,
			<16726 16700 16631 16503 16469 16462>,
			<16722 16705 16635 16500 16466 16461>,
			<16721 16710 16637 16501 16468 16463>,
			<16724 16714 16640 16507 16476 16472>,
			<16732 16719 16647 16509 16477 16473>,
			<16752 16728 16668 16509 16472 16466>,
			<16770 16738 16686 16500 16454 16446>,
			<16745 16712 16694 16500 16456 16450>,
			<16759 16734 16731 16516 16469 16464>,
			<16780 16764 16774 16535 16487 16490>,
			<16807 16809 16819 16559 16518 16523>,
			<16836 16841 16860 16598 16540 16537>,
			<16841 16862 16884 16589 16506 16490>,
			<16825 16842 16863 16555 16476 16465>,
			<16810 16811 16847 16566 16483 16468>,
			<16829 16800 16879 16595 16511 16491>,
			<16829 16800 16879 16595 16511 16491>,
			<16829 16800 16879 16595 16511 16491>;
	};

	qcom,pc-temp-y5-lut {
		qcom,lut-col-legend = <(-10) 0 10 25 40 50>;
		qcom,lut-row-legend = <10000 9800 9600 9400 9200 9000>,
			<8800 8600 8400 8200 8000 7800>,
			<7600 7400 7200 7000 6800 6600>,
			<6400 6200 6000 5800 5600 5400>,
			<5200 5000 4800 4600 4400 4200>,
			<4000 3800 3600 3400 3200 3000>,
			<2800 2600 2400 2200 2000 1800>,
			<1600 1400 1200 1000 900 800>,
			<700 600 500 400 300 200>,
			<100 0>;
		qcom,lut-data = <18689 13536 12642 16157 18242 17572>,
			<15811 13308 13165 16220 18700 19803>,
			<14558 13200 13688 16241 18984 20668>,
			<14566 13202 14159 16230 19132 20674>,
			<15469 13300 14526 16195 19186 20323>,
			<16917 13498 14737 16146 19181 20109>,
			<21307 16323 14771 16026 19066 19092>,
			<26310 20063 14776 15831 18845 17765>,
			<25086 19293 15443 15556 18549 17634>,
			<16979 13948 17529 15153 18071 17712>,
			<12630 11150 18386 14992 17567 17732>,
			<15545 13959 15694 15239 17022 18058>,
			<19263 17486 12652 15518 16512 18372>,
			<18575 17492 13876 15418 16164 18107>,
			<14450 16025 18622 15019 15862 17612>,
			<12476 15357 20617 14696 15585 17091>,
			<14134 17133 18961 14243 15142 16186>,
			<16920 19212 17179 13873 14763 15324>,
			<19709 18988 17510 14433 14705 15048>,
			<22854 17681 18842 16239 14776 14993>,
			<23800 17252 19652 18226 15218 15358>,
			<18746 20046 20053 20925 18728 18139>,
			<13265 22964 20266 22718 21821 20776>,
			<12809 21072 19857 22258 21515 21175>,
			<12795 15342 18911 21034 20457 21369>,
			<12788 12820 18985 20150 19613 21345>,
			<12849 12444 22831 19432 18902 20699>,
			<12932 12278 26111 19067 18239 19819>,
			<13078 12515 23955 19280 17448 18762>,
			<13385 13085 19107 19749 16656 17535>,
			<13560 13375 16945 20200 16522 17021>,
			<13614 13591 15929 20848 16796 16807>,
			<13670 13753 15481 21359 17246 16721>,
			<13811 13856 16463 21650 18439 17622>,
			<14028 14018 18007 21866 20037 19187>,
			<14213 14104 18154 21878 20698 19581>,
			<14434 14180 17194 21800 21040 19577>,
			<14575 14248 16657 21662 21153 19509>,
			<14525 14270 16212 20667 20235 19202>,
			<14372 14268 15285 19285 18998 18832>,
			<14183 14293 14708 18920 18917 19125>,
			<13892 14355 14138 18989 19353 20661>,
			<13609 14303 13928 18238 20157 21625>,
			<13360 14135 13777 16729 20796 21542>,
			<13314 13783 13683 16405 19102 18695>,
			<13677 14164 14046 16611 18161 17246>,
			<13835 14257 13861 15923 17041 17771>,
			<13932 14205 13881 16101 17266 16639>,
			<14071 14299 14431 16519 16721 15972>,
			<14420 14865 15392 16933 16698 15467>,
			<14612 15619 16501 16868 17674 16288>,
			<14304 15292 16542 16641 19878 17868>,
			<13979 14129 14799 16482 20084 19042>,
			<13602 13694 13570 17577 23150 24003>,
			<13602 13694 13570 17577 23150 24003>,
			<13602 13694 13570 17577 23150 24003>;
	};

	qcom,pc-temp-y6-lut {
		qcom,lut-col-legend = <(-10) 0 10 25 40 50>;
		qcom,lut-row-legend = <10000 9800 9600 9400 9200 9000>,
			<8800 8600 8400 8200 8000 7800>,
			<7600 7400 7200 7000 6800 6600>,
			<6400 6200 6000 5800 5600 5400>,
			<5200 5000 4800 4600 4400 4200>,
			<4000 3800 3600 3400 3200 3000>,
			<2800 2600 2400 2200 2000 1800>,
			<1600 1400 1200 1000 900 800>,
			<700 600 500 400 300 200>,
			<100 0>;
		qcom,lut-data = <6292 5786 5353 5078 5028 5020>,
			<6294 5766 5357 5079 5028 5019>,
			<6287 5753 5359 5079 5028 5018>,
			<6273 5745 5359 5079 5028 5018>,
			<6253 5741 5357 5080 5028 5018>,
			<6230 5740 5356 5080 5029 5018>,
			<6192 5746 5352 5080 5029 5018>,
			<6155 5753 5348 5080 5030 5019>,
			<6146 5750 5345 5081 5031 5019>,
			<6145 5732 5344 5082 5032 5021>,
			<6147 5723 5345 5084 5034 5022>,
			<6155 5762 5363 5088 5036 5023>,
			<6164 5811 5384 5092 5037 5025>,
			<6121 5779 5376 5093 5039 5026>,
			<5962 5648 5342 5093 5039 5028>,
			<5884 5586 5322 5093 5041 5029>,
			<5897 5596 5315 5097 5046 5031>,
			<5913 5607 5311 5103 5053 5034>,
			<5914 5602 5308 5111 5057 5038>,
			<5910 5580 5305 5120 5061 5044>,
			<5902 5565 5299 5122 5062 5046>,
			<5869 5560 5279 5105 5058 5045>,
			<5836 5555 5256 5086 5051 5043>,
			<5842 5537 5242 5074 5041 5035>,
			<5870 5507 5231 5066 5027 5020>,
			<5896 5498 5225 5064 5024 5016>,
			<5918 5522 5222 5064 5024 5016>,
			<5939 5557 5219 5064 5025 5017>,
			<5963 5586 5216 5065 5026 5018>,
			<5988 5616 5212 5068 5028 5020>,
			<6015 5648 5214 5069 5030 5022>,
			<6044 5684 5230 5070 5033 5024>,
			<6072 5720 5251 5070 5036 5027>,
			<6098 5756 5273 5071 5038 5030>,
			<6122 5791 5298 5072 5039 5033>,
			<6145 5826 5324 5074 5039 5032>,
			<6167 5858 5350 5078 5035 5025>,
			<6187 5891 5376 5081 5032 5020>,
			<6207 5922 5401 5083 5031 5020>,
			<6225 5954 5424 5084 5031 5021>,
			<6245 5986 5449 5088 5032 5023>,
			<6266 6017 5476 5095 5036 5028>,
			<6293 6046 5509 5099 5037 5028>,
			<6326 6073 5548 5102 5037 5026>,
			<6369 6094 5576 5101 5031 5018>,
			<6350 6055 5576 5105 5034 5023>,
			<6395 6090 5604 5115 5039 5030>,
			<6442 6122 5635 5128 5048 5039>,
			<6499 6160 5666 5142 5058 5050>,
			<6555 6202 5692 5159 5066 5053>,
			<6611 6237 5712 5155 5054 5038>,
			<6670 6264 5723 5149 5047 5031>,
			<6769 6337 5779 5171 5053 5036>,
			<6960 6466 5907 5206 5068 5049>,
			<6960 6466 5907 5206 5068 5049>,
			<6960 6466 5907 5206 5068 5049>;
	};

};
